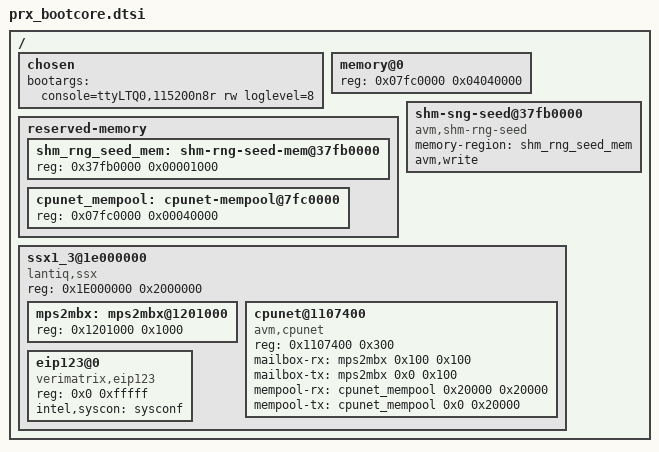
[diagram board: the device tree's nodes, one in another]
/include/ "../prx300-bootcore.dtsi"

/ {
	chosen {
		bootargs = "console=ttyLTQ0,115200n8r rw loglevel=8";
	};

	memory@0 {
		device_type = "memory";
		reg = <0x07fc0000 0x04040000>;
	};

	reserved-memory {
		#address-cells = <1>;
		#size-cells = <1>;
		ranges;

		shm_rng_seed_mem: shm-rng-seed-mem@37fb0000 {
			reg = <0x37fb0000 0x00001000>;
		};

		cpunet_mempool: cpunet-mempool@7fc0000 {
			reg = <0x07fc0000 0x00040000>;
		};
	};

	shm-sng-seed@37fb0000 {
		compatible = "avm,shm-rng-seed";
		memory-region = <&shm_rng_seed_mem>;
		avm,write;
	};

	ssx1_3@1e000000 {
		#address-cells = <1>;
		#size-cells = <1>;
		compatible = "lantiq,ssx", "simple-bus";
		reg = <0x1E000000 0x2000000>; /* 32MB */
		ranges = <0 0x1E000000 0x02000000>;

		mps2mbx: mps2mbx@1201000 {
			reg = <0x1201000 0x1000>;
		};
		cpunet@1107400 {
			compatible = "avm,cpunet";
			reg = <0x1107400 0x300>;
			mailbox-rx = <&mps2mbx 0x100 0x100>;
			mailbox-tx = <&mps2mbx 0x0 0x100>;
			mempool-rx = <&cpunet_mempool 0x20000 0x20000>;
			mempool-tx = <&cpunet_mempool 0x0 0x20000>;
		};

		eip123@0 {
			compatible = "verimatrix,eip123";
			reg = <0x0 0xfffff>;
			intel,syscon = <&sysconf>;
		};
	};
};
